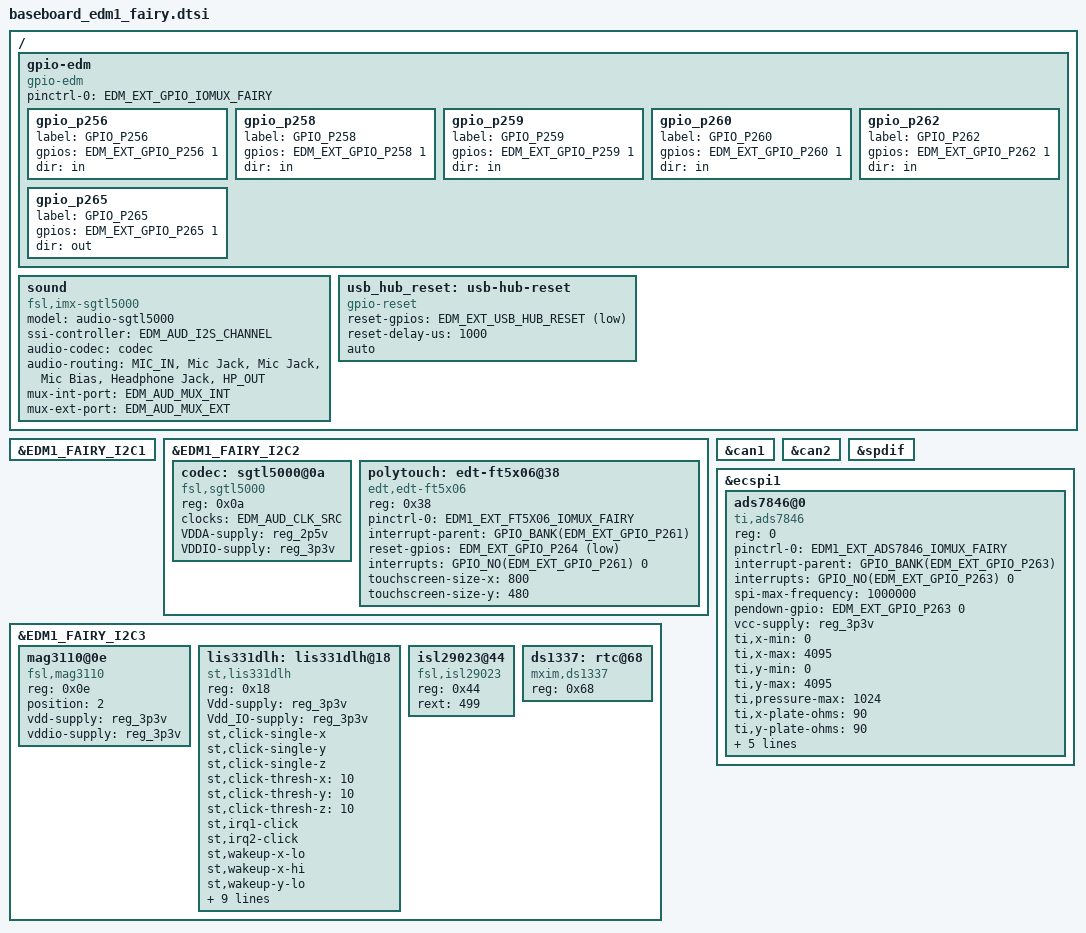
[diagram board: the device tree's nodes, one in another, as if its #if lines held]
/*
 * Copyright 2016 Technexion Ltd.
 *
 * Author: Wig Cheng <wig.cheng@technexion.com>
 *	   Richard Hu <richard.hu@technexion.com>
 *	   Tapani Utriainen <tapani@technexion.com>
 *
 * This program is free software; you can redistribute it and/or modify
 * it under the terms of the GNU General Public License version 2 as
 * published by the Free Software Foundation.
 *
 */

#include <tnmacro.h>

/ {
	gpio-edm {
		compatible = "gpio-edm";
/* custom GPIO may be from GPIO expander on CPU module */
#ifdef EDM_EXT_GPIO_IOMUX_FAIRY
		pinctrl-names = "default";
		pinctrl-0 = <EDM_EXT_GPIO_IOMUX_FAIRY>;
#endif
		gpio_p256 {
			label = "GPIO_P256";
			gpios = <&EDM_EXT_GPIO_P256 1>;
			dir   = "in";
		};
		gpio_p258 {
			label = "GPIO_P258";
			gpios = <&EDM_EXT_GPIO_P258 1>;
			dir   = "in";
		};
		gpio_p259 {
			label = "GPIO_P259";
			gpios = <&EDM_EXT_GPIO_P259 1>;
			dir   = "in";
		};
		gpio_p260 {
			label = "GPIO_P260";
			gpios = <&EDM_EXT_GPIO_P260 1>;
			dir   = "in";
		};
		gpio_p262 {
			label = "GPIO_P262";
			gpios = <&EDM_EXT_GPIO_P262 1>;
			dir   = "in";
		};
#ifdef EDM_EXT_GPIO_P265
		gpio_p265 {
			label = "GPIO_P265";
			gpios = <&EDM_EXT_GPIO_P265 1>;
			dir   = "out";
		};
#endif
	};

	sound {
		compatible = "fsl,imx-sgtl5000",
			     "fsl,imx-audio-sgtl5000";
		model = "audio-sgtl5000";
		ssi-controller = <&EDM_AUD_I2S_CHANNEL>;
		audio-codec = <&codec>;
		audio-routing =
			"MIC_IN", "Mic Jack",
			"Mic Jack", "Mic Bias",
			"Headphone Jack", "HP_OUT";
#if defined(EDM_AUD_MUX_INT) && defined(EDM_AUD_MUX_EXT)
		mux-int-port = <EDM_AUD_MUX_INT>;
		mux-ext-port = <EDM_AUD_MUX_EXT>;
#else
        fsl,no-audmux = "true";
#endif
	};

#ifdef EDM_EXT_USB_HUB_RESET
	usb_hub_reset: usb-hub-reset {
		compatible = "gpio-reset";
		reset-gpios = <&EDM_EXT_USB_HUB_RESET GPIO_ACTIVE_LOW>;
		reset-delay-us = <1000>;
		auto;
	};
#endif
};

&EDM1_FAIRY_I2C1 {
	status = "okay";
};

&EDM1_FAIRY_I2C2 {
	status = "okay";

	codec: sgtl5000@0a {
		compatible = "fsl,sgtl5000";
		reg = <0x0a>;
		clocks = <&EDM_AUD_CLK_SRC>;
		VDDA-supply = <&reg_2p5v>;
		VDDIO-supply = <&reg_3p3v>;
	};

	polytouch: edt-ft5x06@38 {
		compatible = "edt,edt-ft5x06";
		reg = <0x38>;
#ifdef EDM1_EXT_FT5X06_IOMUX_FAIRY
		pinctrl-names = "default";
		pinctrl-0 = <EDM1_EXT_FT5X06_IOMUX_FAIRY>; /* Touch IRQ and Touch Reset */        
#endif
		interrupt-parent = <&GPIO_BANK(EDM_EXT_GPIO_P261)>; /* GPIO_P261 J1B-261 */
		reset-gpios = <&EDM_EXT_GPIO_P264 GPIO_ACTIVE_LOW>; /* GPIO_P264 J1B-264 */
		interrupts = <GPIO_NO(EDM_EXT_GPIO_P261) 0>;
		touchscreen-size-x = <800>;
		touchscreen-size-y = <480>;
	};
};

&EDM1_FAIRY_I2C3 {
	status = "okay";

	mag3110@0e {
		compatible = "fsl,mag3110";
		reg = <0x0e>;
		position = <2>;
		vdd-supply = <&reg_3p3v>;
		vddio-supply = <&reg_3p3v>;
	};

	lis331dlh: lis331dlh@18 {
		compatible = "st,lis331dlh", "st,lis3lv02d";
		reg = <0x18>;
		Vdd-supply = <&reg_3p3v>;
		Vdd_IO-supply = <&reg_3p3v>;

		st,click-single-x;
		st,click-single-y;
		st,click-single-z;
		st,click-thresh-x = <10>;
		st,click-thresh-y = <10>;
		st,click-thresh-z = <10>;
		st,irq1-click;
		st,irq2-click;
		st,wakeup-x-lo;
		st,wakeup-x-hi;
		st,wakeup-y-lo;
		st,wakeup-y-hi;
		st,wakeup-z-lo;
		st,wakeup-z-hi;
		st,min-limit-x = <120>;
		st,min-limit-y = <120>;
		st,min-limit-z = <140>;
		st,max-limit-x = <550>;
		st,max-limit-y = <550>;
		st,max-limit-z = <750>;
	};

	isl29023@44 {
		compatible = "fsl,isl29023";
		reg = <0x44>;
		rext = <499>;
	};

	ds1337: rtc@68 {
		compatible = "mxim,ds1337";
		reg = <0x68>;
	};
};

&can1 {
	status = "okay";
};

&can2 {
	status = "okay";
};

#ifdef EDM1_FAIRY_ENABLE_SPDIF
&spdif {
	status = "okay";
};
#endif

&ecspi1 {
	status = "okay";

	ads7846@0 {
		reg = <0>;  /* CS0 */
		compatible = "ti,ads7846";
#ifdef EDM1_EXT_ADS7846_IOMUX_FAIRY
		pinctrl-names = "default";
		pinctrl-0 = <EDM1_EXT_ADS7846_IOMUX_FAIRY>;
#endif
		interrupt-parent = <&GPIO_BANK(EDM_EXT_GPIO_P263)>; /* GPIO_P263 J1B-263 */
		interrupts = <GPIO_NO(EDM_EXT_GPIO_P263) 0>;
		spi-max-frequency = <1000000>;
		pendown-gpio = <&EDM_EXT_GPIO_P263 0>; /* GPIO_P263 J1B-263 */
		vcc-supply = <&reg_3p3v>;

		ti,x-min = /bits/ 16 <0>;
		ti,x-max = /bits/ 16 <4095>;
		ti,y-min = /bits/ 16 <0>;
		ti,y-max = /bits/ 16 <4095>;
		ti,pressure-max = /bits/ 16 <1024>;
		ti,x-plate-ohms = /bits/ 16 <90>;
		ti,y-plate-ohms = /bits/ 16 <90>;
		ti,debounce-max = /bits/ 16 <70>;
		ti,debounce-tol = /bits/ 16 <3>;
		ti,debounce-rep = /bits/ 16 <2>;
		ti,settle-delay-usec = /bits/ 16 <150>;

		linux,wakeup;
	};
};
